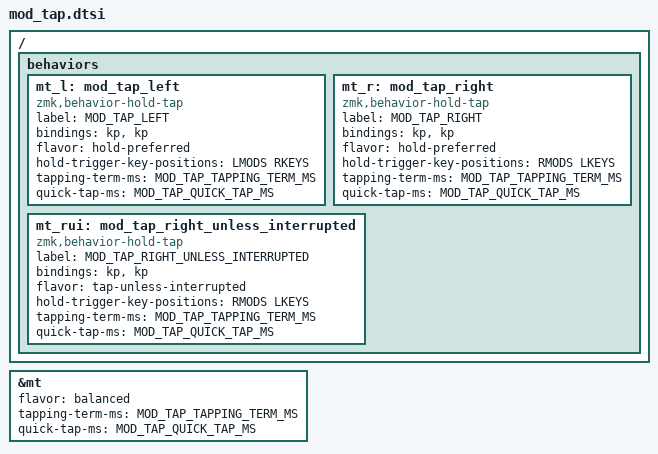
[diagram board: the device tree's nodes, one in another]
#define MOD_TAP_TAPPING_TERM_MS 200
#define MOD_TAP_QUICK_TAP_MS 200

#define LKEYS 0 1 2 3 4 5  12 13 14 15 16 17  24 25 26 27 28 29  36 37 38
#define RKEYS 6 7 8 9 10 11  18 19 20 21 22 23  30 31 32 33 34 35  39 40 41
#define LMODS 13 14 15 37
#define RMODS 20 21 22 40

&mt {
  // flavor = "hold-preferred";
  flavor = "balanced";
  tapping-term-ms = <MOD_TAP_TAPPING_TERM_MS>;
  quick-tap-ms = <MOD_TAP_QUICK_TAP_MS>;
};

/ {
  behaviors {
    mt_l: mod_tap_left {
      compatible = "zmk,behavior-hold-tap";
      label = "MOD_TAP_LEFT";
      #binding-cells = <2>;
      bindings = <&kp>, <&kp>;
      flavor = "hold-preferred";
      hold-trigger-key-positions = <LMODS RKEYS>;
      tapping-term-ms = <MOD_TAP_TAPPING_TERM_MS>;
      quick-tap-ms = <MOD_TAP_QUICK_TAP_MS>;
    };
    mt_r: mod_tap_right {
      compatible = "zmk,behavior-hold-tap";
      label = "MOD_TAP_RIGHT";
      #binding-cells = <2>;
      bindings = <&kp>, <&kp>;
      flavor = "hold-preferred";
      hold-trigger-key-positions = <RMODS LKEYS>;
      tapping-term-ms = <MOD_TAP_TAPPING_TERM_MS>;
      quick-tap-ms = <MOD_TAP_QUICK_TAP_MS>;
    };
    mt_rui: mod_tap_right_unless_interrupted {
      compatible = "zmk,behavior-hold-tap";
      label = "MOD_TAP_RIGHT_UNLESS_INTERRUPTED";
      #binding-cells = <2>;
      bindings = <&kp>, <&kp>;
      flavor = "tap-unless-interrupted";
      hold-trigger-key-positions = <RMODS LKEYS>;
      tapping-term-ms = <MOD_TAP_TAPPING_TERM_MS>;
      quick-tap-ms = <MOD_TAP_QUICK_TAP_MS>;
    };
  };
};
